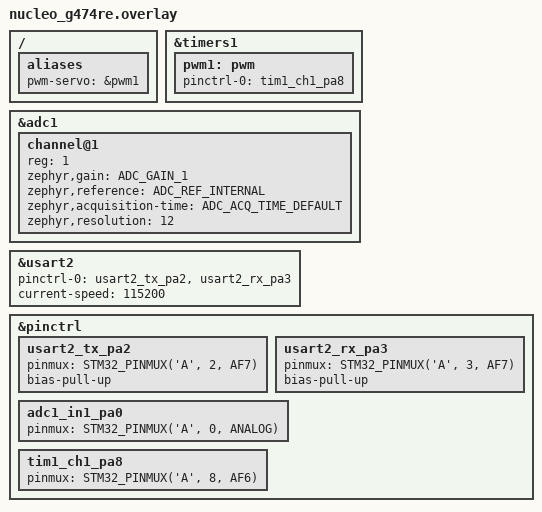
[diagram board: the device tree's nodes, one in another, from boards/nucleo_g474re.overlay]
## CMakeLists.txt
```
cmake_minimum_required(VERSION 3.20.0)
find_package(Zephyr REQUIRED HINTS $ENV{ZEPHYR_BASE})
project(stm32_led_adc)

target_sources(app PRIVATE src/main.c)
```

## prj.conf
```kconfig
# Configuração do Kernel
CONFIG_HEAP_MEM_POOL_SIZE=8192
CONFIG_MAIN_STACK_SIZE=2048
CONFIG_SYSTEM_WORKQUEUE_STACK_SIZE=2048

# Drivers de GPIO
CONFIG_GPIO=y

# Drivers de UART
CONFIG_UART_INTERRUPT_DRIVEN=y
CONFIG_SERIAL=y

# Drivers de ADC
CONFIG_ADC=y
CONFIG_ADC_STM32=y

# Drivers de PWM
CONFIG_PWM=y
CONFIG_PWM_STM32=y
#===========
#CONFIG_DT_HAS_PWM_DEV_ENABLED=y

# Configurações de Console e Logging
CONFIG_CONSOLE=y
CONFIG_UART_CONSOLE=y
CONFIG_PRINTK=y
CONFIG_EARLY_CONSOLE=y

# Heap
CONFIG_SYS_HEAP_RUNTIME_STATS=y

# STM32 específico
CONFIG_CLOCK_CONTROL=y
CONFIG_PINCTRL=y

# Floating point (para cálculos do servo)
CONFIG_FPU=y
CONFIG_FPU_SHARING=y

# Configurações básicas
CONFIG_SERIAL=y
CONFIG_UART_INTERRUPT_DRIVEN=y
CONFIG_PRINTK=y
CONFIG_CONSOLE=y

# Thread e sincronização
CONFIG_NUM_PREEMPT_PRIORITIES=15
CONFIG_TIMESLICING=y
CONFIG_THREAD_STACK_INFO=y

# Heap (se necessário)
CONFIG_HEAP_MEM_POOL_SIZE=8192

# FPU para Cortex-M4
CONFIG_FPU=y
CONFIG_FPU_SHARING=y
```

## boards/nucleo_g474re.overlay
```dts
/* Device Tree Overlay para STM32 Nucleo-G474RE */

/ {
    aliases {
        pwm-servo = &pwm1;
    };
};

&timers1 {
    status = "okay";
    
    pwm1: pwm {
        status = "okay";
        pinctrl-0 = <&tim1_ch1_pa8>;
        pinctrl-names = "default";
    };
};

&adc1 {
    status = "okay";
    #address-cells = <1>;
    #size-cells = <0>;
    channel@1 {
        reg = <1>;
        zephyr,gain = "ADC_GAIN_1";
        zephyr,reference = "ADC_REF_INTERNAL";
        zephyr,acquisition-time = <ADC_ACQ_TIME_DEFAULT>;
        zephyr,resolution = <12>;
    };
};

&usart2 {
    status = "okay";
    pinctrl-0 = <&usart2_tx_pa2 &usart2_rx_pa3>;
    pinctrl-names = "default";
    current-speed = <115200>;
};

&pinctrl {
    /* UART2 - Console via ST-Link */
    usart2_tx_pa2: usart2_tx_pa2 {
        pinmux = <STM32_PINMUX('A', 2, AF7)>;
        bias-pull-up;
    };
    
    usart2_rx_pa3: usart2_rx_pa3 {
        pinmux = <STM32_PINMUX('A', 3, AF7)>;
        bias-pull-up;
    };
    
    /* ADC - Potenciômetro em PA0 */
    adc1_in1_pa0: adc1_in1_pa0 {
        pinmux = <STM32_PINMUX('A', 0, ANALOG)>;
    };
    
    /* PWM - Servo em PA8 */
    tim1_ch1_pa8: tim1_ch1_pa8 {
        pinmux = <STM32_PINMUX('A', 8, AF6)>;
    };
};
```

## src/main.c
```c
#include "config.h"
// Definição das threads
K_THREAD_STACK_DEFINE(adc_thread_stack, 1024);
K_THREAD_STACK_DEFINE(servo_thread_stack, 1024);
static struct k_thread adc_thread_data;
static struct k_thread servo_thread_data;
static k_tid_t adc_tid;
static k_tid_t servo_tid;

// Prioridades
#define ADC_PRIORITY 5
#define SERVO_PRIORITY 4
#define PWM_CHANNEL 0

// Semáforos e mutexes
K_SEM_DEFINE(servo_update_sem, 0, 1);
K_MUTEX_DEFINE(adc_data_mutex);

// Timer para ADC
K_TIMER_DEFINE(adc_timer, NULL, NULL);

// Verifica ADC
#if !DT_NODE_HAS_STATUS(DT_NODELABEL(adc1), okay)
#error "ADC devicetree node is disabled"
#endif

// Verifica PWM
// #if !DT_NODE_EXISTS(PWM_SERVO_CTLR)
// #error "PWM servo alias not found in devicetree"
// #endif

#define PWM_SERVO_CHANNEL 1

static int16_t adc_sample_buffer[1];

// Configuração do ADC
static const struct adc_channel_cfg channel_cfg = {
    .gain = ADC_GAIN,
    .reference = ADC_REFERENCE,
    .acquisition_time = ADC_ACQUISITION_TIME,
    .channel_id = ADC_CHANNEL_ID,
    .differential = 0,
#ifdef CONFIG_ADC_CONFIGURABLE_INPUTS
    .input_positive = ADC_CHANNEL_ID,
#endif
};

// Configuração da leitura do ADC
static const struct adc_sequence adc_seq = {
    .channels = BIT(ADC_CHANNEL_ID),
    .buffer = adc_sample_buffer,
    .buffer_size = sizeof(adc_sample_buffer),
    .resolution = ADC_RESOLUTION,
};

// Variáveis globais para o servo
static uint32_t current_pulse_us = SERVO_MIN_PULSE_US;
static uint16_t current_angle = 0;
static uint16_t current_adc_value = 0;

// Device do PWM
const struct device *pwm_dev;

// Função para converter valor ADC em pulso PWM
uint32_t adc_to_pulse(uint16_t adc_value)
{
    uint32_t pulse = SERVO_MIN_PULSE_US +
                     ((uint32_t)adc_value * (SERVO_MAX_PULSE_US - SERVO_MIN_PULSE_US)) / ADC_MAX_VALUE;
    return pulse;
}

// Função para converter pulso em ângulo
uint16_t pulse_to_angle(uint32_t pulse_us)
{
    return ((pulse_us - SERVO_MIN_PULSE_US) * 180) / (SERVO_MAX_PULSE_US - SERVO_MIN_PULSE_US);
}

// Callback do timer ADC
void adc_timer_callback(struct k_timer *timer)
{
    k_sem_give(&servo_update_sem);
}

// Thread para leitura do ADC
static void adc_thread(void *a, void *b, void *c)
{
    const struct device *adc_dev;
    int32_t ret;
    int32_t adc_raw;

    adc_dev = DEVICE_DT_GET(DT_NODELABEL(adc1));
    if (!device_is_ready(adc_dev))
    {
        printk("ERROR: ADC device not ready\n");
        return;
    }

    ret = adc_channel_setup(adc_dev, &channel_cfg);
    if (ret < 0)
    {
        printk("ERROR: ADC channel setup failed: %d\n", ret);
        return;
    }

    printk("ADC initialized successfully\n");

    k_timer_init(&adc_timer, adc_timer_callback, NULL);
    k_timer_start(&adc_timer, K_MSEC(ADC_READ_INTERVAL_MS), K_MSEC(ADC_READ_INTERVAL_MS));

    while (1)
    {
        k_sem_take(&servo_update_sem, K_FOREVER);

        ret = adc_read(adc_dev, &adc_seq);
        if (ret < 0)
        {
            printk("ERROR: ADC read failed: %d\n", ret);
            continue;
        }

        adc_raw = adc_sample_buffer[0];

        if (k_mutex_lock(&adc_data_mutex, K_MSEC(10)) == 0)
        {
            current_adc_value = (uint16_t)adc_raw;
            current_pulse_us = adc_to_pulse(current_adc_value);
            current_angle = pulse_to_angle(current_pulse_us);
            k_mutex_unlock(&adc_data_mutex);
        }
    }
}

// Thread para controle do servo
static void servo_thread(void *a, void *b, void *c)
{
    int ret;
    uint32_t pulse_us;
    uint16_t angle;
    uint16_t adc_value; // Para leitura segura do ADC
    const struct device *pwm_dev = DEVICE_DT_GET(DT_NODELABEL(pwm1));

    // Declaração do device PWM (local ou global)
    // const struct device *pwm_dev = DEVICE_DT_GET(PWM_SERVO_CTLR);

    if (!device_is_ready(pwm_dev))
    {
        printk("ERROR: PWM device not ready\n");
        return;
    }
    printk("PWM initialized successfully\n");

    // Obtém o device do PWM pelo parent do pwm1
    pwm_dev = DEVICE_DT_GET(DT_PARENT(DT_NODELABEL(pwm1)));
    if (!device_is_ready(pwm_dev))
    {
        printk("ERROR: PWM device not ready\n");
        return;
    }
    printk("PWM initialized successfully\n");

    // Posição inicial (90°)
    uint32_t initial_pulse = (SERVO_MIN_PULSE_US + SERVO_MAX_PULSE_US) / 2;
    ret = pwm_set(pwm_dev, PWM_CHANNEL,
                  PWM_USEC(SERVO_PERIOD_US),
                  PWM_USEC(initial_pulse),
                  PWM_POLARITY_NORMAL);
    if (ret < 0)
    {
        printk("ERROR: Failed to set initial PWM: %d\n", ret);
        return;
    }
    printk("Servo initialized at 90 degrees\n");

    k_msleep(1000);

    uint8_t print_counter = 0;

    while (1)
    {
        // Lê todos os dados de uma vez com o mutex
        if (k_mutex_lock(&adc_data_mutex, K_MSEC(10)) == 0)
        {
            pulse_us = current_pulse_us;
            angle = current_angle;
            adc_value = current_adc_value; // Lê dentro do mutex
            k_mutex_unlock(&adc_data_mutex);
        }
        else
        {
            printk("WARNING: Failed to acquire mutex\n");
            k_msleep(SERVO_UPDATE_INTERVAL_MS);
            continue;
        }

        // Validação adicional (opcional mais recomendado)
        if (pulse_us < SERVO_MIN_PULSE_US || pulse_us > SERVO_MAX_PULSE_US)
        {
            printk("ERROR: Invalid pulse width: %d us\n", pulse_us);
            k_msleep(SERVO_UPDATE_INTERVAL_MS);
            continue;
        }

        // Atualiza PWM do servo
        ret = pwm_set(pwm_dev, PWM_CHANNEL,
                      PWM_USEC(SERVO_PERIOD_US),
                      PWM_USEC(pulse_us),
                      PWM_POLARITY_NORMAL);
        if (ret < 0)
        {
            printk("ERROR: PWM set failed: %d\n", ret);
        }

        // Print periódico (a cada 20 iterações)
        if (++print_counter >= 20)
        {
            printk("ADC: %4d | Pulse: %4d us | Angle: %3d°\n",
                   adc_value, pulse_us, angle);
            print_counter = 0;
        }

        k_msleep(SERVO_UPDATE_INTERVAL_MS);
    }
}

// Comandos via UART
static void uart_cb(const struct device *dev, void *user_data)
{
    static char rx_buf[16];
    static int rx_buf_pos = 0;
    uint8_t c;
    const struct device *uart_dev = DEVICE_DT_GET(DT_NODELABEL(usart2));

    if (!uart_irq_update(uart_dev))
    {
        return;
    }

    if (!uart_irq_rx_ready(uart_dev))
    {
        return;
    }

    while (uart_fifo_read(uart_dev, &c, 1) == 1)
    {
        if ((c == '\r' || c == '\n') && rx_buf_pos > 0)
        {
            rx_buf[rx_buf_pos] = '\0';

            if (strcmp(rx_buf, "status") == 0)
            {
                printk("\n=== SYSTEM STATUS ===\n");
                printk("ADC Value: %d / %d\n", current_adc_value, ADC_MAX_VALUE);
                printk("Pulse Width: %d us\n", current_pulse_us);
                printk("Servo Angle: %d degrees\n", current_angle);
                printk("Uptime: %lld ms\n", k_uptime_get());
                printk("====================\n\n");
            }
            else if (strcmp(rx_buf, "help") == 0)
            {
                printk("\n=== COMMANDS ===\n");
                printk("status - Show system status\n");
                printk("help   - Show this menu\n");
                printk("================\n\n");
            }

            rx_buf_pos = 0;
        }
        else if (rx_buf_pos < (sizeof(rx_buf) - 1))
        {
            rx_buf[rx_buf_pos++] = c;
        }
    }
}

int main(void)
{
    const struct device *uart_dev;

    printk("\n=== STM32 Nucleo-G474RE - Servo Control ===\n");
    printk("Rotate potentiometer to control servo position\n");
    printk("Commands: status, help\n\n");

    sys_heap_init(&app_heap, app_heap_mem, APP_HEAP_SIZE);

    uart_dev = DEVICE_DT_GET(DT_NODELABEL(usart2));
    if (!device_is_ready(uart_dev))
    {
        printk("ERROR: UART device not ready\n");
        return -1;
    }

    uart_irq_callback_user_data_set(uart_dev, uart_cb, NULL);
    uart_irq_rx_enable(uart_dev);

    printk("UART initialized\n");

    adc_tid = k_thread_create(&adc_thread_data, adc_thread_stack,
                              K_THREAD_STACK_SIZEOF(adc_thread_stack),
                              adc_thread, NULL, NULL, NULL, ADC_PRIORITY, 0, K_NO_WAIT);
    k_thread_name_set(adc_tid, "adc_thread");

    servo_tid = k_thread_create(&servo_thread_data, servo_thread_stack,
                                K_THREAD_STACK_SIZEOF(servo_thread_stack),
                                servo_thread, NULL, NULL, NULL, SERVO_PRIORITY, 0, K_NO_WAIT);
    k_thread_name_set(servo_tid, "servo_thread");

    printk("All threads started\n");
    printk("System ready!\n\n");

    while (1)
    {
        k_msleep(1000);
    }

    return 0;
}
```

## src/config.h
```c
#ifndef CONFIG_H
#define CONFIG_H

#include <zephyr/kernel.h>
#include <zephyr/device.h>
#include <zephyr/devicetree.h>
#include <zephyr/drivers/gpio.h>
#include <zephyr/drivers/uart.h>
#include <zephyr/drivers/adc.h>
#include <zephyr/drivers/pwm.h>
#include <zephyr/sys/printk.h>
#include <zephyr/sys/util.h>
#include <string.h>
#include <stdio.h>

/* ========================================================================== */
/* LED DEFINITIONS */
/* ========================================================================== */
#if DT_NODE_HAS_STATUS(DT_ALIAS(led0), okay)
#define LED0_NODE DT_ALIAS(led0)
#elif DT_NODE_HAS_STATUS(DT_ALIAS(led1), okay)
#define LED0_NODE DT_ALIAS(led1)
#elif DT_NODE_HAS_STATUS(DT_ALIAS(led2), okay)
#define LED0_NODE DT_ALIAS(led2)
#else
#warning "Nenhum LED encontrado"
#endif

/* ========================================================================== */
/* PWM SERVO DEFINITIONS */
/* ========================================================================== */
// #define PWM_SERVO_NODE DT_PWMS_CTLR(PWM_SERVO_NODE)

// #if !DT_NODE_EXISTS(PWM_SERVO_NODE)
// #error "pwm-servo alias not found in devicetree"
// #endif

// #define PWM_SERVO_CTLR DT_PARENT(PWM_SERVO_NODE)

/* ========================================================================== */
/* SERVO PARAMETERS */
/* ========================================================================== */
#define SERVO_MIN_PULSE_US 500
#define SERVO_MAX_PULSE_US 2500
#define SERVO_PERIOD_US 20000

/* ========================================================================== */
/* ADC DEFINITIONS */
/* ========================================================================== */
#define ADC_NODE DT_NODELABEL(adc1)
#define ADC_CHANNEL_ID 1
#define ADC_RESOLUTION 12
#define ADC_GAIN ADC_GAIN_1
#define ADC_REFERENCE ADC_REF_INTERNAL
#define ADC_ACQUISITION_TIME ADC_ACQ_TIME_DEFAULT
#define ADC_MAX_VALUE 4095

/* ========================================================================== */
/* TIMING */
/* ========================================================================== */
#define LED_BLINK_INTERVAL_MS 500
#define ADC_READ_INTERVAL_MS 50
#define SERVO_UPDATE_INTERVAL_MS 20

/* ========================================================================== */
/* HEAP */
/* ========================================================================== */
#define APP_HEAP_SIZE 8192
static uint8_t __aligned(4) app_heap_mem[APP_HEAP_SIZE];
static struct sys_heap app_heap;

#endif // CONFIG_H
```
